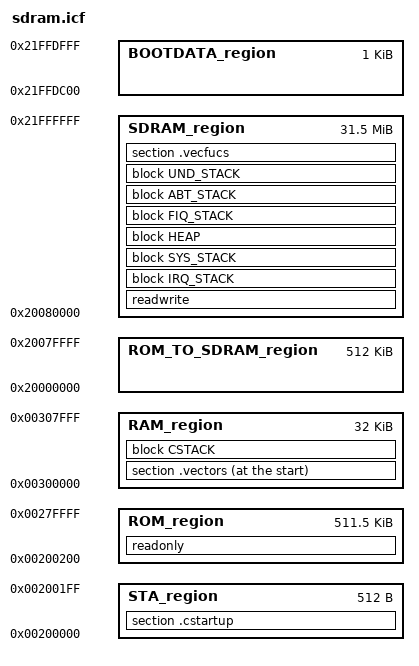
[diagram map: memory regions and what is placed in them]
/*###ICF### Section handled by ICF editor, don't touch! ****/
/*-Editor annotation file-*/
/* IcfEditorFile="$TOOLKIT_DIR$\config\ide\IcfEditor\a_v1_0.xml" */
/*-Memory Regions-*/
define symbol __ICFEDIT_region_ROM_start__   = 0x200000;
define symbol __ICFEDIT_region_ROM_end__     = 0x27FFFF;
define symbol __ICFEDIT_region_ROM_TO_SDRAM_start__ = 0x20000000;
define symbol __ICFEDIT_region_ROM_TO_SDRAM_end__   = 0x2007FFFF;
define symbol __ICFEDIT_region_SDRAM_start__ = 0x20080000;
define symbol __ICFEDIT_region_SDRAM_end__   = 0x21FFFFFF;
define symbol __ICFEDIT_region_RAM_start__   = 0x300000;
define symbol __ICFEDIT_region_RAM_end__     = 0x307FFF;

define symbol __ICFEDIT_region_BOOTDATA_start__ = 0x21FFDC00;
define symbol __ICFEDIT_region_BOOTDATA_end__   = 0x21FFDFFF;

/*-Sizes-*/
define symbol __ICFEDIT_size_startup__  = 0x200;
define symbol __ICFEDIT_size_vectors__  = 0x200;
define symbol __ICFEDIT_size_cstack__   = 0x2000;
define symbol __ICFEDIT_size_sysstack__ = 0x1000;

define symbol __ICFEDIT_size_fiqstack__ = 0x100;
define symbol __ICFEDIT_size_abtstack__ = 0x100;
define symbol __ICFEDIT_size_undstack__ = 0x100;

define symbol __ICFEDIT_size_irqstack__ = 0x1000;
define symbol __ICFEDIT_size_heap__     = 0x0;
/*-Exports-*/
export symbol __ICFEDIT_region_ROM_start__;
export symbol __ICFEDIT_region_ROM_end__;
export symbol __ICFEDIT_region_SDRAM_start__;
export symbol __ICFEDIT_region_SDRAM_end__;
export symbol __ICFEDIT_region_RAM_start__;
export symbol __ICFEDIT_region_RAM_end__;
export symbol __ICFEDIT_size_startup__;
export symbol __ICFEDIT_size_vectors__;
export symbol __ICFEDIT_size_cstack__;
export symbol __ICFEDIT_size_sysstack__;
export symbol __ICFEDIT_size_irqstack__;

export symbol __ICFEDIT_size_fiqstack__;
export symbol __ICFEDIT_size_abtstack__;
export symbol __ICFEDIT_size_undstack__;

export symbol __ICFEDIT_size_heap__;
/**** End of ICF editor section. ###ICF###*/

define memory mem with size = 4G;
define region STA_region = mem:[from __ICFEDIT_region_ROM_start__ size __ICFEDIT_size_startup__];
define region ROM_region = mem:[from __ICFEDIT_region_ROM_start__+__ICFEDIT_size_startup__ to __ICFEDIT_region_ROM_end__];
//define region VEC_region = mem:[from __ICFEDIT_region_RAM_start__ size __ICFEDIT_size_vectors__];
define region RAM_region = mem:[from __ICFEDIT_region_RAM_start__ to __ICFEDIT_region_RAM_end__];

//define region SDRAM_VEC_region = mem:[from __ICFEDIT_region_RAM_start__ size __ICFEDIT_size_vectors__];
define region SDRAM_region = 	 mem:[from __ICFEDIT_region_SDRAM_start__ to __ICFEDIT_region_SDRAM_end__];
define region ROM_TO_SDRAM_region = 	 mem:[from __ICFEDIT_region_ROM_TO_SDRAM_start__ to __ICFEDIT_region_ROM_TO_SDRAM_end__];

define region BOOTDATA_region =  mem:[from __ICFEDIT_region_BOOTDATA_start__ to __ICFEDIT_region_BOOTDATA_end__];

define block CSTACK    with alignment = 8, size = __ICFEDIT_size_cstack__   { };
define block SYS_STACK with alignment = 8, size = __ICFEDIT_size_sysstack__ { };
define block IRQ_STACK with alignment = 8, size = __ICFEDIT_size_irqstack__ { };

define block FIQ_STACK with alignment = 8, size = __ICFEDIT_size_fiqstack__ { };
define block ABT_STACK with alignment = 8, size = __ICFEDIT_size_abtstack__ { };
define block UND_STACK with alignment = 8, size = __ICFEDIT_size_undstack__ { };

define block HEAP      with alignment = 8, size = __ICFEDIT_size_heap__     { };

initialize by copy { readwrite };
initialize by copy { section .vectors, section .vecfucs };
do not initialize  { section .noinit };

place in STA_region { section .cstartup };
place in ROM_region { readonly };
place at start of RAM_region { section .vectors };
place in RAM_region {block CSTACK };
place in SDRAM_region {readwrite, block IRQ_STACK, block SYS_STACK, block HEAP, block FIQ_STACK, block ABT_STACK, block UND_STACK, section .vecfucs };


